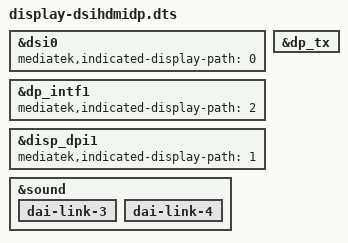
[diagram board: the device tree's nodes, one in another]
/dts-v1/;
/plugin/;

#include <dt-bindings/pinctrl/mt8195-pinfunc.h>

/ {
	fragment@0 {
		target = <&dsi0>;
		__overlay__ {
			mediatek,indicated-display-path = <0>;
		};
	};

	fragment@1 {
		target = <&dp_tx>;
		__overlay__ {
			status = "okay";
		};
	};

	fragment@2 {
		target = <&dp_intf1>;
		__overlay__ {
			status = "okay";
			mediatek,indicated-display-path = <2>;
		};
	};

	fragment@3 {
		target = <&disp_dpi1>;
		__overlay__ {
			mediatek,indicated-display-path = <1>;
		};
	};

	fragment@4 {
		target = <&sound>;
		__overlay__ {
			dai-link-3 { /* HDMI */
				status = "okay";
			};

			dai-link-4 { /* DPTX */
				status = "okay";
			};
		};
	};
};
